# ATtiny84 register map
Vendor: Atmel; File version: 1.0
CPU: other r0p0, little endian, no MPU, no FPU, 4 interrupt priority bits
Registers are 8-bit, read-write, reset 0x0 unless marked. A register's access mark holds for its fields unless they carry their own. Offsets are from the block's base; [hi:lo] are bit positions.

## EEPROM
Base 0x0000003C
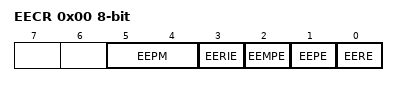
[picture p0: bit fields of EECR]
0x00 EECR — EEPROM Control Register
  [5:4] EEPM — EEPROM Programming Mode Bits
    0=Erase and Write in one operation; 1=Erase Only; 2=Write Only
  [3] EERIE — EEPROM Ready Interrupt Enable
  [2] EEMPE — EEPROM Master Write Enable
  [1] EEPE — EEPROM Write Enable
  [0] EERE — EEPROM Read Enable
0x01 EEDR — EEPROM Data Register
0x02 EEAR 16-bit (reset mask 0xFF) — EEPROM Address Register Bytes

## EXINT — External Interrupts
Base 0x00000032
0x00 PCMSK0 — Pin Change Enable Mask 0
0x0E PCMSK1 — Pin Change Enable Mask 1
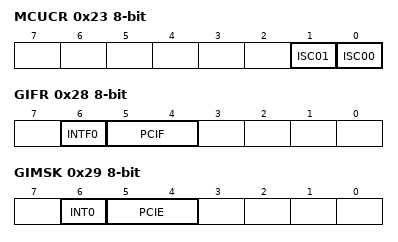
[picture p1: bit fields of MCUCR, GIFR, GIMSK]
0x23 MCUCR — MCU Control Register
  [1] ISC01 — Interrupt Sense Control 0 Bit 1
  [0] ISC00 — Interrupt Sense Control 0 Bit 0
    0=Low Level of INTX; 1=Any Logical Change of INTX
0x28 GIFR — General Interrupt Flag register
  [6] INTF0 — External Interrupt Flag 0
  [5:4] PCIF — Pin Change Interrupt Flags
0x29 GIMSK — General Interrupt Mask Register
  [6] INT0 — External Interrupt Request 0 Enable
  [5:4] PCIE — Pin Change Interrupt Enables

## LOCKBIT — Lockbits
Base 0x00000000
0x00 LOCKBIT
  [1:0] LB — Memory Lock
    0=PROG_VER_DISABLED (Further programming and verification disabled); 2=PROG_DISABLED (Further programming disabled); 3=NO_LOCK (No memory lock features enabled)

## PORTA — I/O Port
Base 0x00000039
0x00 PINA — Port A Input Pins
0x01 DDRA — Port A Data Direction Register
0x02 PORTA — Port A Data Register

## PORTB — I/O Port
Base 0x00000036
0x00 PINB — Input Pins, Port B
0x01 DDRB — Data Direction Register, Port B
0x02 PORTB — Data Register, Port B

## TC0 — Timer/Counter, 8-bit
Base 0x00000043
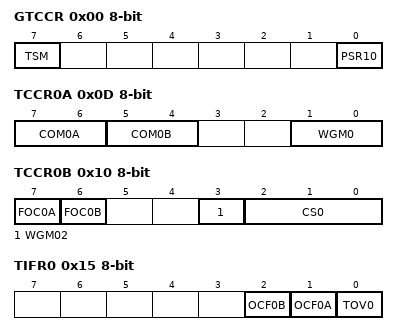
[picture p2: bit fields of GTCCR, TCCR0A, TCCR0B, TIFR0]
0x00 GTCCR — General Timer/Counter Control Register
  [7] TSM — Timer/Counter Synchronization Mode
  [0] PSR10 — Prescaler Reset Timer/CounterN
0x0D TCCR0A — Timer/Counter Control Register A
  [7:6] COM0A — Compare Match Output A Mode bits
  [5:4] COM0B — Compare Match Output B Mode bits
  [1:0] WGM0 — Waveform Generation Mode bits
0x0F TCNT0 — Timer/Counter0
0x10 TCCR0B — Timer/Counter Control Register B
  [7] FOC0A — Force Output Compare A
  [6] FOC0B — Force Output Compare B
  [3] WGM02 — Waveform Generation Mode bit 2
  [2:0] CS0 — Clock Select bits
    0=No Clock Source (Stopped); 1=Running, No Prescaling; 2=Running, CLK/8; 3=Running, CLK/64; 4=Running, CLK/256; 5=Running, CLK/1024; 6=Running, ExtClk Tn Falling Edge; 7=Running, ExtClk Tn Rising Edge
0x13 OCR0A — Timer/Counter0 Output Compare Register A
0x15 TIFR0 — Timer/Counter0 Interrupt Flag Register
  [2] OCF0B — Timer/Counter0 Output Compare Flag B
  [1] OCF0A — Timer/Counter0 Output Compare Flag A
  [0] TOV0 — Timer/Counter0 Overflow Flag
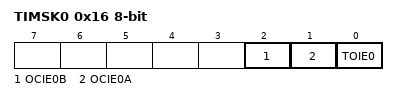
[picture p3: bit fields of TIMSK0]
0x16 TIMSK0 — Timer/Counter Interrupt Mask Register
  [2] OCIE0B — Timer/Counter0 Output Compare Match B Interrupt Enable
  [1] OCIE0A — Timer/Counter0 Output Compare Match A Interrupt Enable
  [0] TOIE0 — Timer/Counter0 Overflow Interrupt Enable
0x19 OCR0B — Timer/Counter0 Output Compare Register B

## TC1 — Timer/Counter, 16-bit
Base 0x0000002B
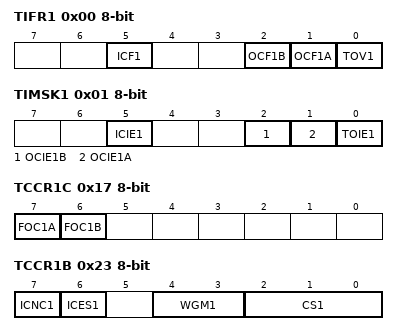
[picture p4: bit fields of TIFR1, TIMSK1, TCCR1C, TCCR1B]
0x00 TIFR1 — Timer/Counter Interrupt Flag register
  [5] ICF1 — Timer/Counter1 Input Capture Flag
  [2] OCF1B — Timer/Counter1 Output Compare B Match Flag
  [1] OCF1A — Timer/Counter1 Output Compare A Match Flag
  [0] TOV1 — Timer/Counter1 Overflow Flag
0x01 TIMSK1 — Timer/Counter1 Interrupt Mask Register
  [5] ICIE1 — Timer/Counter1 Input Capture Interrupt Enable
  [2] OCIE1B — Timer/Counter1 Output Compare B Match Interrupt Enable
  [1] OCIE1A — Timer/Counter1 Output Compare A Match Interrupt Enable
  [0] TOIE1 — Timer/Counter1 Overflow Interrupt Enable
0x17 TCCR1C — Timer/Counter1 Control Register C
  [7] FOC1A — Force Output Compare for Channel A
  [6] FOC1B — Force Output Compare for Channel B
0x19 ICR1 16-bit (reset mask 0xFF) — Timer/Counter1 Input Capture Register Bytes
0x1D OCR1B 16-bit (reset mask 0xFF) — Timer/Counter1 Output Compare Register B Bytes
0x1F OCR1A 16-bit (reset mask 0xFF) — Timer/Counter1 Output Compare Register A Bytes
0x21 TCNT1 16-bit (reset mask 0xFF) — Timer/Counter1 Bytes
0x23 TCCR1B — Timer/Counter1 Control Register B
  [7] ICNC1 — Input Capture 1 Noise Canceler
  [6] ICES1 — Input Capture 1 Edge Select
  [4:3] WGM1 — Waveform Generation Mode Bits
  [2:0] CS1 — Clock Select1 bits
    0=No Clock Source (Stopped); 1=Running, No Prescaling; 2=Running, CLK/8; 3=Running, CLK/64; 4=Running, CLK/256; 5=Running, CLK/1024; 6=Running, ExtClk Tn Falling Edge; 7=Running, ExtClk Tn Rising Edge
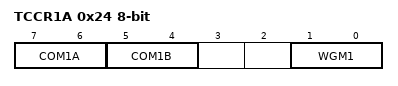
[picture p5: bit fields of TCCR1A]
0x24 TCCR1A — Timer/Counter1 Control Register A
  [7:6] COM1A — Compare Output Mode 1A, bits
  [5:4] COM1B — Compare Output Mode 1B, bits
  [1:0] WGM1 — Pulse Width Modulator Select Bits

## USI — Universal Serial Interface
Base 0x0000002D
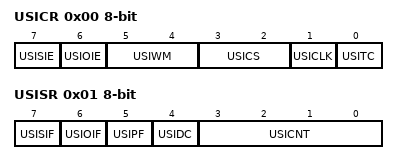
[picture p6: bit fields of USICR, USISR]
0x00 USICR — USI Control Register
  [7] USISIE — Start Condition Interrupt Enable
  [6] USIOIE — Counter Overflow Interrupt Enable
  [5:4] USIWM — USI Wire Mode Bits
    0=Normal Operation; 1=Three-Wire Mode; 2=Two-Wire Mode; 3=Two-Wire Mode Held Low
  [3:2] USICS — USI Clock Source Select Bits
  [1] USICLK — Clock Strobe
  [0] USITC — Toggle Clock Port Pin
0x01 USISR — USI Status Register
  [7] USISIF — Start Condition Interrupt Flag
  [6] USIOIF — Counter Overflow Interrupt Flag
  [5] USIPF — Stop Condition Flag
  [4] USIDC — Data Output Collision
  [3:0] USICNT — USI Counter Value Bits
0x02 USIDR — USI Data Register
0x03 USIBR — USI Buffer Register

## WDT — Watchdog Timer
Base 0x00000041
0x00 WDTCSR — Watchdog Timer Control Register
  [7] WDIF — Watchdog Timeout Interrupt Flag
  [6] WDIE — Watchdog Timeout Interrupt Enable
  [4] WDCE — Watchdog Change Enable
  [3] WDE — Watch Dog Enable
  [5:0] WDP — Watchdog Timer Prescaler Bits
    0=Oscillator Cycles 2K; 1=Oscillator Cycles 4K; 2=Oscillator Cycles 8K; 3=Oscillator Cycles 16K; 4=Oscillator Cycles 32K; 5=Oscillator Cycles 64K; 6=Oscillator Cycles 128K; 7=Oscillator Cycles 256K
